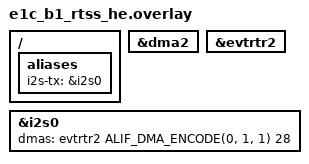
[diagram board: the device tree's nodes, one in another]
/*
 * SPDX-FileCopyrightText: Copyright Alif Semiconductor
 * SPDX-License-Identifier: Apache-2.0
 */

/*
 * I2S_0 => Speaker Output
 */

#include <zephyr/dt-bindings/dma/alif_dma_event_router.h>
&dma2 {
	status = "okay";
};

&evtrtr2 {
	status = "okay";
};

&i2s0 {
	/*
	 * Cell 0: ALIF_DMA_ENCODE(channel, dma_group, handshake)
	 *   - channel: Physical DMA channel (0 for TX)
	 *   - dma_group: Input source selection (1)
	 *   - handshake: Enable hardware handshaking (1 for I2S)
	 * Cell 1: Peripheral request number (28 for TX)
	 */
	dmas = <&evtrtr2 ALIF_DMA_ENCODE(0, 1, 1) 28>;
	dma-names = "txdma";
	status = "okay";
};

/ {
	aliases {
		i2s-tx = &i2s0;
	};
};
